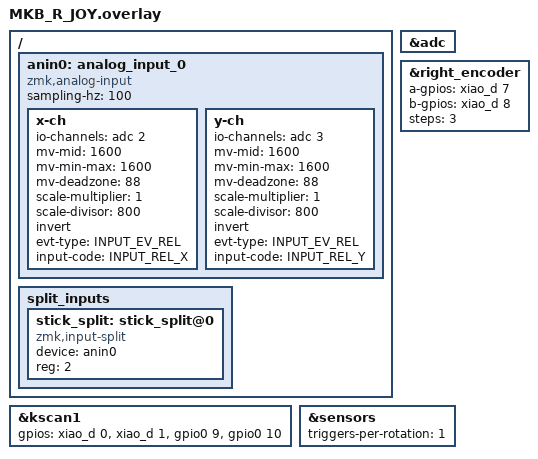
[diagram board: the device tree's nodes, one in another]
#include <zephyr/dt-bindings/input/input-event-codes.h>
#include <input/processors.dtsi>
#include <dt-bindings/zmk/input_transform.h>
#include <dt-bindings/zmk/keys.h>

&kscan1 {
    gpios
        = <&xiao_d  0 (GPIO_ACTIVE_HIGH)>
        , <&xiao_d  1 (GPIO_ACTIVE_HIGH)>
        /* Exclude D2, D3 (&xiao_d 2, 3) to avoid conflict with ADC for joystick */
        , <&gpio0   9 (GPIO_ACTIVE_HIGH)>
        , <&gpio0  10 (GPIO_ACTIVE_HIGH)>
        ;
};

&adc {
	status = "okay";
};

&right_encoder{
    a-gpios = <&xiao_d 7 (GPIO_ACTIVE_HIGH | GPIO_PULL_UP)>;
    b-gpios = <&xiao_d 8 (GPIO_ACTIVE_HIGH | GPIO_PULL_UP)>;
    steps = <3>;
    status = "okay";
};

&sensors {
    triggers-per-rotation = <1>;
};

/ {
    anin0: analog_input_0 {
        compatible = "zmk,analog-input";
        sampling-hz = <100>;
        x-ch {
            io-channels = <&adc 2>;
            mv-mid = <1600>;
            mv-min-max = <1600>;
            mv-deadzone = <88>;
            scale-multiplier = <1>;
            scale-divisor = <800>;
            invert;
            evt-type = <INPUT_EV_REL>;
            input-code = <INPUT_REL_X>;
        };
        y-ch {
            io-channels = <&adc 3>;
            mv-mid = <1600>;
            mv-min-max = <1600>;
            mv-deadzone = <88>;
            scale-multiplier = <1>;
            scale-divisor = <800>;
            invert;
            evt-type = <INPUT_EV_REL>;
            input-code = <INPUT_REL_Y>;
        };
    };

    split_inputs {
        #address-cells = <1>;
        #size-cells = <0>;

        stick_split: stick_split@0 {
            compatible = "zmk,input-split";
            status = "okay";
            device = <&anin0>;
            reg = <2>;
        };
    };
};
